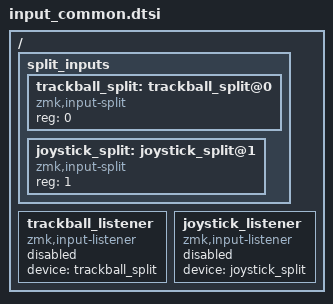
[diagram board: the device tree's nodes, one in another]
#include <dt-bindings/zmk/input_transform.h>
#include <input/processors.dtsi>

/ {
  split_inputs {
    #address-cells = <1>;
    #size-cells = <0>;

    trackball_split: trackball_split@0 {
      compatible = "zmk,input-split";
      reg = <0>;
    };

    joystick_split: joystick_split@1 {
      compatible = "zmk,input-split";
      reg = <1>;
    };
  };

  trackball_listener: trackball_listener {
    compatible = "zmk,input-listener";
    status = "disabled";
    device = <&trackball_split>;
    };

  joystick_listener: joystick_listener {
    compatible = "zmk,input-listener";
    status = "disabled";
    device = <&joystick_split>;
  };
};
